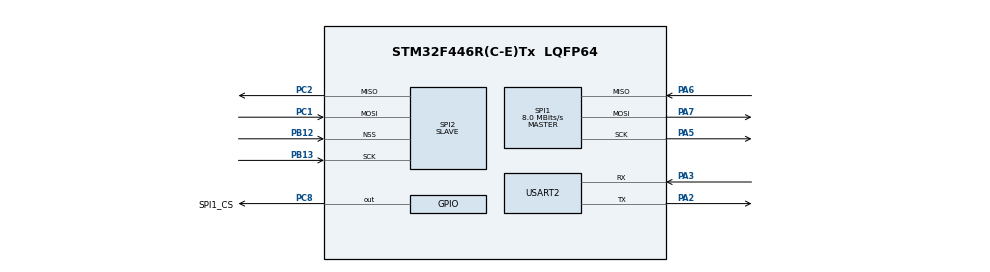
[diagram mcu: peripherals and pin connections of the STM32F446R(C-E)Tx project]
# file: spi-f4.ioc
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Mcu.Family=STM32F4
Mcu.Name=STM32F446R(C-E)Tx
Mcu.Package=LQFP64
NVIC.PriorityGroup=NVIC_PRIORITYGROUP_4
NVIC.SPI1_IRQn=true\:0\:0\:false\:false\:true\:true
NVIC.SPI2_IRQn=true\:0\:0\:false\:false\:true\:true
PA2.Mode=Asynchronous
PA2.Signal=USART2_TX
PA3.Mode=Asynchronous
PA3.Signal=USART2_RX
PA5.Mode=Full_Duplex_Master
PA5.Signal=SPI1_SCK
PA6.Mode=Full_Duplex_Master
PA6.Signal=SPI1_MISO
PA7.Mode=Full_Duplex_Master
PA7.Signal=SPI1_MOSI
PB12.Mode=NSS_Signal_Hard_Input
PB12.Signal=SPI2_NSS
PB13.Mode=Full_Duplex_Slave
PB13.Signal=SPI2_SCK
PC1.Mode=Full_Duplex_Slave
PC1.Signal=SPI2_MOSI
PC2.Mode=Full_Duplex_Slave
PC2.Signal=SPI2_MISO
PC8.GPIO_Label=SPI1_CS
PC8.GPIO_Speed=GPIO_SPEED_FREQ_VERY_HIGH
PC8.Signal=GPIO_Output
ProjectManager.HeapSize=0x200
ProjectManager.StackSize=0x400
ProjectManager.TargetToolchain=TrueSTUDIO
RCC.CortexFreq_Value=16000000
RCC.USBFreq_Value=96000000
RCC.VCOOutputFreq_Value=192000000
SPI1.CalculateBaudRate=8.0 MBits/s
SPI1.Direction=SPI_DIRECTION_2LINES
SPI1.Mode=SPI_MODE_MASTER
SPI1.VirtualType=VM_MASTER
SPI2.Direction=SPI_DIRECTION_2LINES
SPI2.Mode=SPI_MODE_SLAVE
SPI2.VirtualNSS=VM_NSSHARD
SPI2.VirtualType=VM_SLAVE
USART2.VirtualMode=VM_ASYNC
board=custom

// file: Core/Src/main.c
/**
  ******************************************************************************
  * @file           : main.c
  * @brief          : Main program body
  ******************************************************************************
  ** This notice applies to any and all portions of this file
  * that are not between comment pairs USER CODE BEGIN and
  * USER CODE END. Other portions of this file, whether
  * inserted by the user or by software development tools
  * are owned by their respective copyright owners.
  *
  * COPYRIGHT(c) 2018 STMicroelectronics
  *
  * Redistribution and use in source and binary forms, with or without modification,
  * are permitted provided that the following conditions are met:
  *   1. Redistributions of source code must retain the above copyright notice,
  *      this list of conditions and the following disclaimer.
  *   2. Redistributions in binary form must reproduce the above copyright notice,
  *      this list of conditions and the following disclaimer in the documentation
  *      and/or other materials provided with the distribution.
  *   3. Neither the name of STMicroelectronics nor the names of its contributors
  *      may be used to endorse or promote products derived from this software
  *      without specific prior written permission.
  *
  * THIS SOFTWARE IS PROVIDED BY THE COPYRIGHT HOLDERS AND CONTRIBUTORS "AS IS"
  * AND ANY EXPRESS OR IMPLIED WARRANTIES, INCLUDING, BUT NOT LIMITED TO, THE
  * IMPLIED WARRANTIES OF MERCHANTABILITY AND FITNESS FOR A PARTICULAR PURPOSE ARE
  * DISCLAIMED. IN NO EVENT SHALL THE COPYRIGHT HOLDER OR CONTRIBUTORS BE LIABLE
  * FOR ANY DIRECT, INDIRECT, INCIDENTAL, SPECIAL, EXEMPLARY, OR CONSEQUENTIAL
  * DAMAGES (INCLUDING, BUT NOT LIMITED TO, PROCUREMENT OF SUBSTITUTE GOODS OR
  * SERVICES; LOSS OF USE, DATA, OR PROFITS; OR BUSINESS INTERRUPTION) HOWEVER
  * CAUSED AND ON ANY THEORY OF LIABILITY, WHETHER IN CONTRACT, STRICT LIABILITY,
  * OR TORT (INCLUDING NEGLIGENCE OR OTHERWISE) ARISING IN ANY WAY OUT OF THE USE
  * OF THIS SOFTWARE, EVEN IF ADVISED OF THE POSSIBILITY OF SUCH DAMAGE.
  *
  ******************************************************************************
  */
#include "main.h"
#include "stm32f4xx_hal.h"
#include "spi.h"
#include "usart.h"
#include "gpio.h"

/* USER CODE BEGIN PV */
/* Private variables ---------------------------------------------------------*/

/* USER CODE END PV */

void SystemClock_Config(void);

/* USER CODE BEGIN PFP */
/* Private function prototypes -----------------------------------------------*/

/* USER CODE END PFP */

uint8_t tx1[7] = "asd\n";
uint8_t rx1[7];
uint8_t tx2[7] = "lol\n";
uint8_t rx2[7];

int main(void)
{

  /* MCU Configuration----------------------------------------------------------*/

  /* Reset of all peripherals, Initializes the Flash interface and the Systick. */
  HAL_Init();

  /* Configure the system clock */
  SystemClock_Config();

  /* Initialize all configured peripherals */
  MX_GPIO_Init();
  MX_USART2_UART_Init();
  MX_SPI1_Init();
  MX_SPI2_Init();

  /* Infinite loop */
  /* USER CODE BEGIN WHILE */
  //HAL_SPI_Receive_IT(&hspi2, rx, 1);
  //HAL_SPI_Receive_IT(&hspi1, rx2, 1);

  while (1)
  {

  /* USER CODE END WHILE */

  /* USER CODE BEGIN 3 */

	  HAL_GPIO_WritePin(SPI1_CS_GPIO_Port, SPI1_CS_Pin, GPIO_PIN_RESET);
	  HAL_SPI_Transmit(&hspi1, tx1, 1, HAL_MAX_DELAY);
	  HAL_GPIO_WritePin(SPI1_CS_GPIO_Port, SPI1_CS_Pin, GPIO_PIN_SET);

	  HAL_SPI_Receive(&hspi2, rx2, 1, HAL_MAX_DELAY);

	  HAL_UART_Transmit(&huart2, rx2, 1, HAL_MAX_DELAY);

	  HAL_Delay(1000);
  }
  /* USER CODE END 3 */

}

void HAL_SPI_RxHalfCpltCallback(SPI_HandleTypeDef *hspi)
{
	/*if (hspi == &hspi1)
	{
		HAL_SPI_Receive_IT(&hspi1, rx2, 1);
	}
	else*/ if (hspi == &hspi2)
	{
		//HAL_SPI_Receive_IT(&hspi2, rx, 1);
		//HAL_UART_Transmit(&huart2, rx, 1, HAL_MAX_DELAY);
	}
}

void SystemClock_Config(void)
{

  RCC_OscInitTypeDef RCC_OscInitStruct;
  RCC_ClkInitTypeDef RCC_ClkInitStruct;

    /**Configure the main internal regulator output voltage
    */
  __HAL_RCC_PWR_CLK_ENABLE();

  __HAL_PWR_VOLTAGESCALING_CONFIG(PWR_REGULATOR_VOLTAGE_SCALE3);

    /**Initializes the CPU, AHB and APB busses clocks
    */
  RCC_OscInitStruct.OscillatorType = RCC_OSCILLATORTYPE_HSI;
  RCC_OscInitStruct.HSIState = RCC_HSI_ON;
  RCC_OscInitStruct.HSICalibrationValue = 16;
  RCC_OscInitStruct.PLL.PLLState = RCC_PLL_NONE;
  if (HAL_RCC_OscConfig(&RCC_OscInitStruct) != HAL_OK)
  {
    _Error_Handler(__FILE__, __LINE__);
  }

    /**Initializes the CPU, AHB and APB busses clocks
    */
  RCC_ClkInitStruct.ClockType = RCC_CLOCKTYPE_HCLK|RCC_CLOCKTYPE_SYSCLK
                              |RCC_CLOCKTYPE_PCLK1|RCC_CLOCKTYPE_PCLK2;
  RCC_ClkInitStruct.SYSCLKSource = RCC_SYSCLKSOURCE_HSI;
  RCC_ClkInitStruct.AHBCLKDivider = RCC_SYSCLK_DIV1;
  RCC_ClkInitStruct.APB1CLKDivider = RCC_HCLK_DIV1;
  RCC_ClkInitStruct.APB2CLKDivider = RCC_HCLK_DIV1;

  if (HAL_RCC_ClockConfig(&RCC_ClkInitStruct, FLASH_LATENCY_0) != HAL_OK)
  {
    _Error_Handler(__FILE__, __LINE__);
  }

    /**Configure the Systick interrupt time
    */
  HAL_SYSTICK_Config(HAL_RCC_GetHCLKFreq()/1000);

    /**Configure the Systick
    */
  HAL_SYSTICK_CLKSourceConfig(SYSTICK_CLKSOURCE_HCLK);

  /* SysTick_IRQn interrupt configuration */
  HAL_NVIC_SetPriority(SysTick_IRQn, 0, 0);
}

void _Error_Handler(char *file, int line)
{
  while(1)
  {
  }
}

/************************ (C) COPYRIGHT STMicroelectronics *****END OF FILE****/
